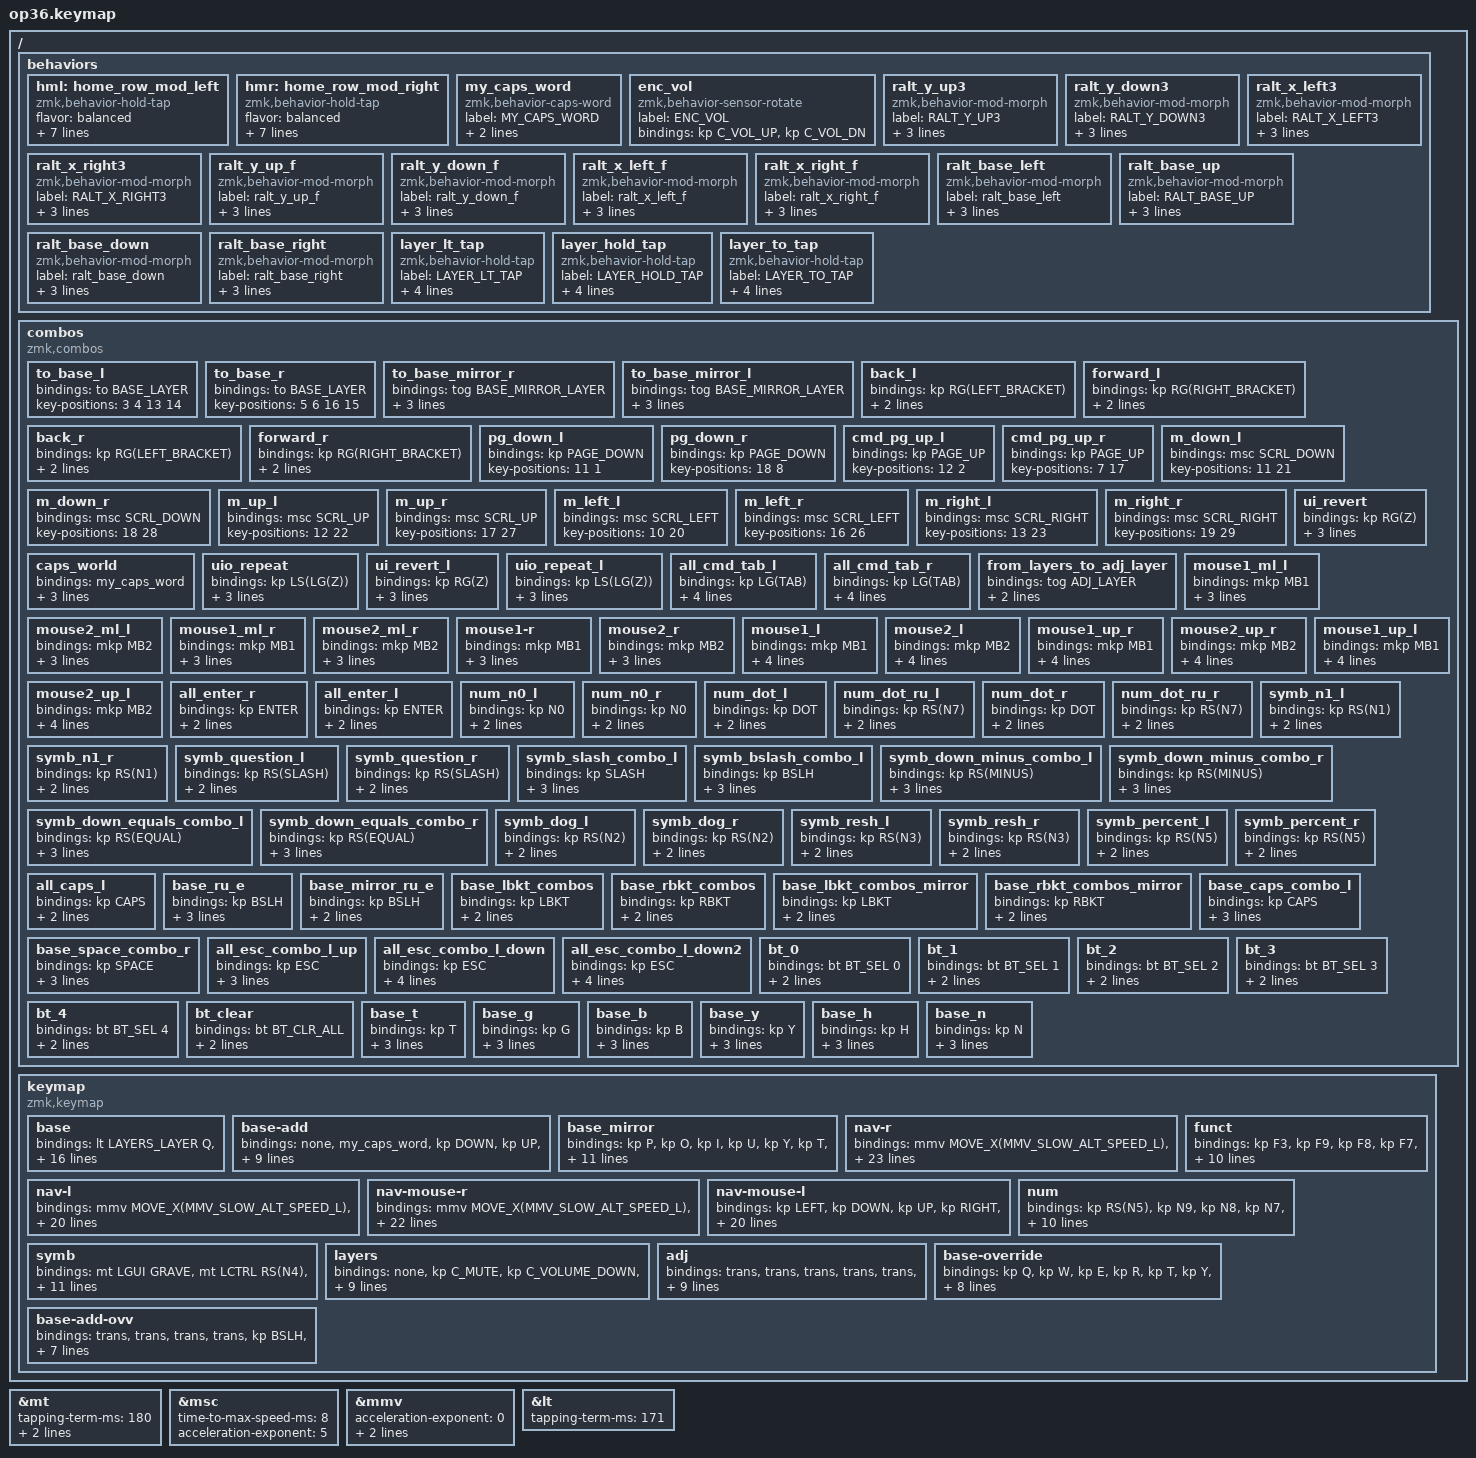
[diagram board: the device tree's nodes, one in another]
#define ZMK_POINTING_DEFAULT_SCRL_VAL 25

// Константы для перемещений

#define BASE_LAYER 0
#define BASE_ADD_LAYER 1
#define BASE_MIRROR_LAYER 2
#define NAV_R_LAYER 3
#define NAV_L_LAYER 4
#define NAV_MOUSE_R_LAYER 5
#define NAV_MOUSE_L_LAYER 6
#define FUNCT_LAYER 7
#define NUM_LAYER 8
#define SYMB_LAYER 9
#define LAYERS_LAYER 10
#define ADJ_LAYER 11
#define BASE_OVERRIDE_LAYER 12
#define BASE_ADD_OVERRIDE_LAYER 13

#define MMV_SLOW_ALT_SPEED 250
#define MMV_SLOW_ALT_SPEED_L -250
#define MMV_SLOW_ALT_SPEED_U -250
#define MMV_SLOW_ALT_SPEED_D 250
#define MMV_SLOW_ALT_SPEED_R 250

//

#define MMV_FAST_ALT_SPEED_X 950
#define MMV_FAST_ALT_SPEED_Y 950
#define MMV_FAST_ALT_SPEED_L -950
#define MMV_FAST_ALT_SPEED_U -950
#define MMV_FAST_ALT_SPEED_D 950
#define MMV_FAST_ALT_SPEED_R 950

//

#define MMV_FAST_SPEED_X 700
#define MMV_FAST_SPEED_Y 480
#define MMV_FAST_SPEED_L -MMV_FAST_SPEED_X
#define MMV_FAST_SPEED_U -MMV_FAST_SPEED_Y
#define MMV_FAST_SPEED_D MMV_FAST_SPEED_Y
#define MMV_FAST_SPEED_R MMV_FAST_SPEED_X

//
// 1100x750, 700x480, 600x410
#define MMV_SUPER_FAST_SPEED_X 1100
#define MMV_SUPER_FAST_SPEED_Y 750
#define MMV_SUPER_FAST_SPEED_L -MMV_SUPER_FAST_SPEED_X
#define MMV_SUPER_FAST_SPEED_U -MMV_SUPER_FAST_SPEED_Y
#define MMV_SUPER_FAST_SPEED_D MMV_SUPER_FAST_SPEED_Y
#define MMV_SUPER_FAST_SPEED_R MMV_SUPER_FAST_SPEED_X

#include <behaviors.dtsi>
#include <dt-bindings/zmk/bt.h>
#include <dt-bindings/zmk/keys.h>
#include <dt-bindings/zmk/outputs.h>
#include <dt-bindings/zmk/pointing.h>
#include "keys_ru.h"

&mt {
  tapping-term-ms = <180>;
  flavor = "balanced";
  quick-tap-ms = <50>;
};

&msc {
  time-to-max-speed-ms = <8>;
  acceleration-exponent = <5>;
};

&mmv {
  acceleration-exponent = <0>;
  time-to-max-speed-ms = <100>;
  delay-ms = <0>;
};

&lt {
  tapping-term-ms = <171>;
};

/ {
    behaviors {
        hml: home_row_mod_left {
            compatible = "zmk,behavior-hold-tap";
            #binding-cells = <2>;
            flavor = "balanced";
            require-prior-idle-ms = <150>;
            tapping-term-ms = <220>;
            quick-tap-ms = <175>;
            bindings = <&kp>, <&kp>;

            hold-trigger-key-positions = <5 6 7 8 9 15 16 17 18 19 25 26 27 28 29 33 34 35>;
            hold-trigger-on-release;
        };

        hmr: home_row_mod_right {
            compatible = "zmk,behavior-hold-tap";
            #binding-cells = <2>;
            flavor = "balanced";
            require-prior-idle-ms = <150>;
            tapping-term-ms = <220>;
            quick-tap-ms = <175>;
            bindings = <&kp>, <&kp>;

            hold-trigger-key-positions = <0 1 2 3 4 10 11 12 13 14 20 21 22 23 24 30 31 32>;
            hold-trigger-on-release;
        };        
        
         my_caps_word: my_caps_word {
                compatible = "zmk,behavior-caps-word";
                label = "MY_CAPS_WORD";
                #binding-cells = <0>;
                continue-list = <UNDERSCORE MINUS COMMA PERIOD SEMICOLON SPACE>;
             };
                    
            enc_vol: enc_vol {
              compatible = "zmk,behavior-sensor-rotate";
              label = "ENC_VOL";
              #sensor-binding-cells = <0>;
              bindings = <&kp C_VOL_UP>, <&kp C_VOL_DN>;
            };
            
            ralt_y_up3: ralt_y_up3 {
              compatible = "zmk,behavior-mod-morph";
              label = "RALT_Y_UP3";
              #binding-cells = <0>;
              bindings = 
                <&mmv MOVE_Y(MMV_SLOW_ALT_SPEED_U)>,
                <&mmv MOVE_Y(MMV_SUPER_FAST_SPEED_U)>;
              mods = <(MOD_RALT)>;
            };
        
            ralt_y_down3: ralt_y_down3 {
              compatible = "zmk,behavior-mod-morph";
              label = "RALT_Y_DOWN3";
              #binding-cells = <0>;
              bindings = 
                <&mmv MOVE_Y(MMV_SLOW_ALT_SPEED_D)>,
                <&mmv MOVE_Y(MMV_SUPER_FAST_SPEED_D)>;
              mods = <(MOD_RALT)>;
            };
        
            ralt_x_left3: ralt_x_left3 {
              compatible = "zmk,behavior-mod-morph";
              label = "RALT_X_LEFT3";
              #binding-cells = <0>;
              bindings =
                <&mmv MOVE_X(MMV_SLOW_ALT_SPEED_L)>,
                <&mmv MOVE_X(MMV_SUPER_FAST_SPEED_L)>;
              mods = <(MOD_RALT)>;
            };
        
            ralt_x_right3: ralt_x_right3 {
              compatible = "zmk,behavior-mod-morph";
              label = "RALT_X_RIGHT3";
              #binding-cells = <0>;
              bindings =
                <&mmv MOVE_X(MMV_SLOW_ALT_SPEED_R)>,
                <&mmv MOVE_X(MMV_SUPER_FAST_SPEED_R)>;
              mods = <(MOD_RALT)>;
            };
            
            /* */
            ralt_y_up_f: ralt_y_up_f {
                  compatible = "zmk,behavior-mod-morph";
                  label = "ralt_y_up_f";
                  #binding-cells = <0>;
                  bindings = 
                    <&kp UP_ARROW>,
                    <&mmv MOVE_Y(MMV_SUPER_FAST_SPEED_U)>;
                  mods = <(MOD_RALT)>;
                };
            
                ralt_y_down_f: ralt_y_down_f {
                  compatible = "zmk,behavior-mod-morph";
                  label = "ralt_y_down_f";
                  #binding-cells = <0>;
                  bindings = 
                    <&kp DOWN>,
                    <&mmv MOVE_Y(MMV_SUPER_FAST_SPEED_D)>;
                  mods = <(MOD_RALT)>;
                };
            
                ralt_x_left_f: ralt_x_left_f {
                  compatible = "zmk,behavior-mod-morph";
                  label = "ralt_x_left_f";
                  #binding-cells = <0>;
                  bindings =
                    <&kp LEFT>,
                    <&mmv MOVE_X(MMV_SUPER_FAST_SPEED_L)>;
                  mods = <(MOD_RALT)>;
                };
            
                ralt_x_right_f: ralt_x_right_f {
                  compatible = "zmk,behavior-mod-morph";
                  label = "ralt_x_right_f";
                  #binding-cells = <0>;
                  bindings =
                    <&kp RIGHT>,
                    <&mmv MOVE_X(MMV_SUPER_FAST_SPEED_R)>;
                  mods = <(MOD_RALT)>;
                };
            /* */
        
            /* mouse 0 layer */
            ralt_base_left: ralt_base_left {
              compatible = "zmk,behavior-mod-morph";
              label = "ralt_base_left";
              #binding-cells = <0>;
              bindings =
                <&kp M>,
                <&mmv MOVE_X(MMV_SUPER_FAST_SPEED_L)>;
              mods = <(MOD_RALT)>;
            };
        
            ralt_base_up: ralt_base_up {
              compatible = "zmk,behavior-mod-morph";
              label = "RALT_BASE_UP";
              #binding-cells = <0>;
              bindings = 
                <&kp COMMA>,
                <&mmv MOVE_Y(MMV_SUPER_FAST_SPEED_U)>;
              mods = <(MOD_RALT)>;
            };
        
            ralt_base_down: ralt_base_down {
              compatible = "zmk,behavior-mod-morph";
              label = "ralt_base_down";
              #binding-cells = <0>;
              bindings = 
                <&kp DOT>,
                <&mmv MOVE_Y(MMV_SUPER_FAST_SPEED_D)>;
              mods = <(MOD_RALT)>;
            };
        
            ralt_base_right: ralt_base_right {
              compatible = "zmk,behavior-mod-morph";
              label = "ralt_base_right";
              #binding-cells = <0>;
              bindings =
                <&kp SLASH>,
                <&mmv MOVE_X(MMV_SUPER_FAST_SPEED_R)>;
              mods = <(MOD_RALT)>;
            };
            /* end mouse 0 layer */
        
            layer_lt_tap: layer_lt_tap {
              compatible = "zmk,behavior-hold-tap";
              label = "LAYER_LT_TAP";
              #binding-cells = <2>;
              tapping-term-ms = <180>;
              quick-tap-ms = <0>;
              flavor = "tap-preferred";
              bindings = <&lt>, <&kp>;
            };
        
            layer_hold_tap: layer_hold_tap {
              compatible = "zmk,behavior-hold-tap";
              label = "LAYER_HOLD_TAP";
              #binding-cells = <2>;
              tapping-term-ms = <180>;
              quick-tap-ms = <0>;
              flavor = "tap-preferred";
              bindings = <&tog>, <&kp>;
            };
            
            layer_to_tap: layer_to_tap {
              compatible = "zmk,behavior-hold-tap";
              label = "LAYER_TO_TAP";
              #binding-cells = <2>;
              tapping-term-ms = <180>;
              quick-tap-ms = <0>;
              flavor = "tap-preferred";
              bindings = <&to>, <&kp>;
            };
    };

    combos {
        compatible = "zmk,combos";
                
        /* mo-start */
        to_base_l {
            bindings = <&to BASE_LAYER>;
            key-positions = <3 4 13 14>;
        };
        
        to_base_r {
            bindings = <&to BASE_LAYER>;
            key-positions = <5 6 16 15>;                    
        };
        
        to_base_mirror_r {
            bindings = <&tog BASE_MIRROR_LAYER>;
            key-positions = <0 1 2>;
            layers = <
                BASE_LAYER
                BASE_ADD_LAYER
                BASE_OVERRIDE_LAYER
                BASE_ADD_OVERRIDE_LAYER
                BASE_MIRROR_LAYER
            >;            
        };
        
        to_base_mirror_l {
            bindings = <&tog BASE_MIRROR_LAYER>;
            key-positions = <7 8 9>;
            layers = <
                BASE_LAYER
                BASE_ADD_LAYER
                BASE_OVERRIDE_LAYER
                BASE_ADD_OVERRIDE_LAYER
                BASE_MIRROR_LAYER
            >;                    
        };              
        /* mo-end */
        
        /* nav-start */
        back_l {
            bindings = <&kp RG(LEFT_BRACKET)>;
            key-positions = <12 13>;
            layers = <FUNCT_LAYER>;
        };

        forward_l {
            bindings = <&kp RG(RIGHT_BRACKET)>;
            key-positions = <11 12>;
            layers = <FUNCT_LAYER>;
        };

        back_r {
            bindings = <&kp RG(LEFT_BRACKET)>;
            key-positions = <16 17>;
            layers = <FUNCT_LAYER>;
        };

        forward_r {
            bindings = <&kp RG(RIGHT_BRACKET)>;
            key-positions = <17 18>;
            layers = <FUNCT_LAYER>;
        };

        /* nav-end */
        
        /* mouse-start */
        pg_down_l {
            bindings = <&kp PAGE_DOWN>;
            key-positions = <11 1>;
        };

        pg_down_r {
            bindings = <&kp PAGE_DOWN>;
            key-positions = <18 8>;
        };        
        
        cmd_pg_up_l {
            bindings = <&kp PAGE_UP>;
            key-positions = <12 2>;
        };

        cmd_pg_up_r {
            bindings = <&kp PAGE_UP>;
            key-positions = <7 17>;
        };

        m_down_l {
            bindings = <&msc SCRL_DOWN>;
            key-positions = <11 21>;
        };

        m_down_r {
            bindings = <&msc SCRL_DOWN>;
            key-positions = <18 28>;
        };

        m_up_l {
            bindings = <&msc SCRL_UP>;
            key-positions = <12 22>;
        };

        m_up_r {
            bindings = <&msc SCRL_UP>;
            key-positions = <17 27>;
        };

        m_left_l {
            bindings = <&msc SCRL_LEFT>;
            key-positions = <10 20>;
        };

        m_left_r {
            bindings = <&msc SCRL_LEFT>;
            key-positions = <16 26>;
        };

        m_right_l {
            bindings = <&msc SCRL_RIGHT>;
            key-positions = <13 23>;
        };

        m_right_r {
            bindings = <&msc SCRL_RIGHT>;
            key-positions = <19 29>;
        };        
        /* mouse-end */
        
        /* system-start */
        caps_world {
            bindings = <&my_caps_word>;
            key-positions = <16 13 17 12>;
            layers = <BASE_LAYER BASE_ADD_LAYER BASE_MIRROR_LAYER BASE_OVERRIDE_LAYER BASE_ADD_OVERRIDE_LAYER>;
        };        
        
        ui_revert {
            bindings = <&kp RG(Z)>;
            key-positions = <6 7>;
            layers = <FUNCT_LAYER BASE_OVERRIDE_LAYER LAYERS_LAYER>;
        };

        uio_repeat {
            bindings = <&kp LS(LG(Z))>;
            key-positions = <7 8>;
            layers = <FUNCT_LAYER BASE_OVERRIDE_LAYER LAYERS_LAYER>;
        };

        ui_revert_l {
            bindings = <&kp RG(Z)>;
            key-positions = <2 3>;
            layers = <FUNCT_LAYER BASE_OVERRIDE_LAYER LAYERS_LAYER>;
        };

        uio_repeat_l {
            bindings = <&kp LS(LG(Z))>;
            key-positions = <2 1>;
            layers = <FUNCT_LAYER BASE_OVERRIDE_LAYER LAYERS_LAYER>;
        };        
        
        all_cmd_tab_l {
            bindings = <&kp LG(TAB)>;
            key-positions = <2 1>;
            require-prior-idle-ms = <150>;
                        layers = <
                            BASE_LAYER
                            BASE_ADD_LAYER
                            BASE_MIRROR_LAYER
                            NAV_R_LAYER
                            NAV_L_LAYER
                            NAV_MOUSE_R_LAYER
                            NAV_MOUSE_L_LAYER
                            FUNCT_LAYER
                            NUM_LAYER
                            /* SYMB_LAYER */
                            LAYERS_LAYER
                            ADJ_LAYER
                            BASE_OVERRIDE_LAYER
                            BASE_ADD_OVERRIDE_LAYER
                        >;
        };

        all_cmd_tab_r {
            bindings = <&kp LG(TAB)>;
            require-prior-idle-ms = <150>;
            key-positions = <9 8>;
                        layers = <
                            BASE_LAYER
                            BASE_ADD_LAYER
                            BASE_MIRROR_LAYER
                            NAV_R_LAYER
                            NAV_L_LAYER
                            NAV_MOUSE_R_LAYER
                            NAV_MOUSE_L_LAYER
                            FUNCT_LAYER
                            NUM_LAYER
                            /* SYMB_LAYER */
                            LAYERS_LAYER
                            ADJ_LAYER
                            BASE_OVERRIDE_LAYER
                            BASE_ADD_OVERRIDE_LAYER
                        >;
        };        
        /* system-end */                

        from_layers_to_adj_layer {
            bindings = <&tog ADJ_LAYER>;
            key-positions = <9 8>;
            layers = <FUNCT_LAYER
            LAYERS_LAYER
            ADJ_LAYER>;
        };

        mouse1_ml_l {
            bindings = <&mkp MB1>;
            key-positions = <13 12>;
            require-prior-idle-ms = <150>;
            layers = <
            NAV_MOUSE_R_LAYER
            NAV_MOUSE_L_LAYER
            >;
        };

        mouse2_ml_l {
            bindings = <&mkp MB2>;
            key-positions = <13 12 11>;
            require-prior-idle-ms = <150>;
            layers = <
            NAV_MOUSE_R_LAYER
            NAV_MOUSE_L_LAYER
            >;
        };

        mouse1_ml_r {
            bindings = <&mkp MB1>;
            key-positions = <16 17>;
            require-prior-idle-ms = <150>;
            layers = <
            NAV_MOUSE_R_LAYER
            NAV_MOUSE_L_LAYER
            >;
        };

        mouse2_ml_r {
            bindings = <&mkp MB2>;
            key-positions = <16 17 18>;
            require-prior-idle-ms = <150>;
            layers = <
            NAV_MOUSE_R_LAYER
            NAV_MOUSE_L_LAYER
            >;
        };

        mouse1-r {
            bindings = <&mkp MB1>;
            key-positions = <26 27>;
            layers = <
                NAV_R_LAYER
                NAV_L_LAYER
                NAV_MOUSE_R_LAYER
                NAV_MOUSE_L_LAYER
                FUNCT_LAYER
                /* NUM_LAYER
                SYMB_LAYER */
                LAYERS_LAYER
                ADJ_LAYER
            >;            
        };

        mouse2_r {
            bindings = <&mkp MB2>;
            key-positions = <26 27 28>;
            layers = <
                NAV_R_LAYER
                NAV_L_LAYER
                NAV_MOUSE_R_LAYER
                NAV_MOUSE_L_LAYER
                FUNCT_LAYER
                /* NUM_LAYER
                SYMB_LAYER */
                LAYERS_LAYER
                ADJ_LAYER
            >;            
        };

        mouse1_l {
            bindings = <&mkp MB1>;
            key-positions = <22 23>;
            require-prior-idle-ms = <150>;
            layers = <
                BASE_LAYER
                BASE_ADD_LAYER
                BASE_MIRROR_LAYER
                NAV_R_LAYER
                NAV_L_LAYER
                NAV_MOUSE_R_LAYER
                NAV_MOUSE_L_LAYER
                FUNCT_LAYER
                /* NUM_LAYER
                SYMB_LAYER */
                LAYERS_LAYER
                ADJ_LAYER
                BASE_OVERRIDE_LAYER
                BASE_ADD_OVERRIDE_LAYER
            >;
        };

        mouse2_l {
            bindings = <&mkp MB2>;
            key-positions = <21 22 23>;
            require-prior-idle-ms = <150>;
            layers = <
                BASE_LAYER
                BASE_ADD_LAYER
                BASE_MIRROR_LAYER
                NAV_R_LAYER
                NAV_L_LAYER
                NAV_MOUSE_R_LAYER
                NAV_MOUSE_L_LAYER
                FUNCT_LAYER
                /* NUM_LAYER
                SYMB_LAYER */
                LAYERS_LAYER
                ADJ_LAYER
                BASE_OVERRIDE_LAYER
                BASE_ADD_OVERRIDE_LAYER
            >;            
        };

        mouse1_up_r {
            bindings = <&mkp MB1>;
            key-positions = <7 6>;
            require-prior-idle-ms = <150>;
            layers = <
            NAV_R_LAYER
            NAV_L_LAYER
            NAV_MOUSE_R_LAYER
            NAV_MOUSE_L_LAYER
            >;
        };

        mouse2_up_r {
            bindings = <&mkp MB2>;
            key-positions = <6 7 8>;
            require-prior-idle-ms = <150>;
            layers = <
            NAV_R_LAYER
            NAV_L_LAYER
            NAV_MOUSE_R_LAYER
            NAV_MOUSE_L_LAYER
            >;
        };

        mouse1_up_l {
            bindings = <&mkp MB1>;
            key-positions = <3 2>;
            require-prior-idle-ms = <150>;
            layers = <
            NAV_R_LAYER
            NAV_L_LAYER
            NAV_MOUSE_R_LAYER
            NAV_MOUSE_L_LAYER
            >;
        };

        mouse2_up_l {
            bindings = <&mkp MB2>;
            key-positions = <3 2 1>;
            require-prior-idle-ms = <150>;
            layers = <
            NAV_R_LAYER
            NAV_L_LAYER
            NAV_MOUSE_R_LAYER
            NAV_MOUSE_L_LAYER
            >;
        };
        
        /* kp-start */
        all_enter_r {
            bindings = <&kp ENTER>;
            key-positions = <27 28>;
            require-prior-idle-ms = <70>;
        };

        all_enter_l {
            bindings = <&kp ENTER>;
            key-positions = <22 21>;
            require-prior-idle-ms = <70>;
        };

        num_n0_l {
            bindings = <&kp N0>;
            key-positions = <23 22>;
            layers = <NUM_LAYER>;
        };

        num_n0_r {
            bindings = <&kp N0>;
            key-positions = <26 27>;
            layers = <NUM_LAYER>;
        };
        
        num_dot_l {
                    bindings = <&kp DOT>;
                    key-positions = <2 3>;
                    layers = <NUM_LAYER>;
                };
               
        num_dot_ru_l {
                    bindings = <&kp RS(N7)>;
                    key-positions = <1 2>;
                    layers = <NUM_LAYER>;
                };        
        
        num_dot_r {
                    bindings = <&kp DOT>;
                    key-positions = <6 7>;
                    layers = <NUM_LAYER>;
                };

        num_dot_ru_r {
                    bindings = <&kp RS(N7)>;
                    key-positions = <7 8>;
                    layers = <NUM_LAYER>;
                };                
        
        symb_n1_l {
            bindings = <&kp RS(N1)>;
            key-positions = <2 3>;
            layers = <SYMB_LAYER>;
        };
        
        symb_n1_r {
            bindings = <&kp RS(N1)>;
            key-positions = <6 7>;
            layers = <SYMB_LAYER>;      
        };
        
        symb_question_l {
            bindings = <&kp RS(SLASH)>;
            key-positions = <1 2>;
            layers = <SYMB_LAYER>;
        };
        
        symb_question_r {
            bindings = <&kp RS(SLASH)>;
            key-positions = <7 8>;
            layers = <SYMB_LAYER>;      
        };
        
        symb_slash_combo_l {
            bindings = <&kp SLASH>;
            key-positions = <12 13>;
            require-prior-idle-ms = <150>;
            layers = <SYMB_LAYER>;
        };
        
        symb_bslash_combo_l {
            bindings = <&kp BSLH>;
            key-positions = <11 12>;
            require-prior-idle-ms = <150>;
            layers = <SYMB_LAYER>;
        };        
        
        symb_down_minus_combo_l {
                    bindings = <&kp RS(MINUS)>;
                    key-positions = <11 12>;
                    require-prior-idle-ms = <150>;
                    layers = <SYMB_LAYER>;
                };
        
        symb_down_minus_combo_r {
            bindings = <&kp RS(MINUS)>;
            key-positions = <16 17>;
            require-prior-idle-ms = <150>;
            layers = <SYMB_LAYER>;
        };
        
        symb_down_equals_combo_l {
                    bindings = <&kp RS(EQUAL)>;
                    key-positions = <12 13>;
                    require-prior-idle-ms = <150>;
                    layers = <SYMB_LAYER>;
                };
        
        symb_down_equals_combo_r {
            bindings = <&kp RS(EQUAL)>;
            key-positions = <17 18>;
            require-prior-idle-ms = <150>;
            layers = <SYMB_LAYER>;
        };
        
        symb_dog_l {
            bindings = <&kp RS(N2)>;
            key-positions = <1 2 3>;
            layers = <SYMB_LAYER>;
        };
                        
        symb_dog_r {
            bindings = <&kp RS(N2)>;
            key-positions = <6 7 8>;
            layers = <SYMB_LAYER>;
        };                        

        symb_resh_l {
            bindings = <&kp RS(N3)>;
            key-positions = <11 12 13>;
            layers = <SYMB_LAYER>;
        };
        
        symb_resh_r {
            bindings = <&kp RS(N3)>;
            key-positions = <16 17 18>;
            layers = <SYMB_LAYER>;
        };
        
        symb_percent_l {
            bindings = <&kp RS(N5)>;
            key-positions = <21 22 23>;
            layers = <SYMB_LAYER>;      
        };        
                
        symb_percent_r {
            bindings = <&kp RS(N5)>;
            key-positions = <26 27 28>;
            layers = <SYMB_LAYER>;      
        };                                               
        
        all_caps_l {
            bindings = <&kp CAPS>;
            key-positions = <40 41 24 23>;
            require-prior-idle-ms = <150>;
        };        
        
        base_ru_e {
            bindings = <&kp BSLH>;
            key-positions = <2 3>;
            layers = <BASE_LAYER BASE_ADD_LAYER BASE_OVERRIDE_LAYER BASE_ADD_OVERRIDE_LAYER>;
        };
        
        base_mirror_ru_e {
            bindings = <&kp BSLH>;
            key-positions = <6 7>;
            layers = <BASE_MIRROR_LAYER>;
        };        
        
        base_lbkt_combos {
            bindings = <&kp LBKT>;
            key-positions = <6 7>;
            layers = <BASE_LAYER BASE_ADD_LAYER>;
        };

        base_rbkt_combos {
            bindings = <&kp RBKT>;
            key-positions = <8 7>;
            layers = <BASE_LAYER BASE_ADD_LAYER>;
        };
        
        base_lbkt_combos_mirror {
            bindings = <&kp LBKT>;
            key-positions = <2 3>;
            layers = <BASE_MIRROR_LAYER>;
        };

        base_rbkt_combos_mirror {
            bindings = <&kp RBKT>;
            key-positions = <1 2>;
            layers = <BASE_MIRROR_LAYER>;
        };        

        base_caps_combo_l {
            bindings = <&kp CAPS>;
            key-positions = <14 13>;
            layers = <BASE_LAYER BASE_ADD_LAYER BASE_OVERRIDE_LAYER BASE_ADD_OVERRIDE_LAYER>;
        };
        
        base_space_combo_r {
            bindings = <&kp SPACE>;
            key-positions = <28 29>;
            layers = <BASE_LAYER BASE_ADD_LAYER BASE_OVERRIDE_LAYER BASE_ADD_OVERRIDE_LAYER>;
        };        

        all_esc_combo_l_up {
            bindings = <&kp ESC>;
            key-positions = <0 1>;
                        layers = <
                            BASE_LAYER
                            BASE_ADD_LAYER
                            BASE_MIRROR_LAYER
                            NAV_R_LAYER
                            NAV_L_LAYER
                            NAV_MOUSE_R_LAYER
                            NAV_MOUSE_L_LAYER
                            FUNCT_LAYER
                            NUM_LAYER
                            /* SYMB_LAYER */
                            LAYERS_LAYER
                            ADJ_LAYER
                            BASE_OVERRIDE_LAYER
                            BASE_ADD_OVERRIDE_LAYER
                        >;
        };
        
        all_esc_combo_l_down {
            bindings = <&kp ESC>;
            key-positions = <23 24>;
                        layers = <
                            BASE_LAYER
                            BASE_ADD_LAYER
                            BASE_MIRROR_LAYER
                            NAV_R_LAYER
                            NAV_L_LAYER
                            NAV_MOUSE_R_LAYER
                            NAV_MOUSE_L_LAYER
                            FUNCT_LAYER
                            NUM_LAYER
                            /* SYMB_LAYER */
                            LAYERS_LAYER
                            ADJ_LAYER
                            BASE_OVERRIDE_LAYER
                            BASE_ADD_OVERRIDE_LAYER
                        >;
            require-prior-idle-ms = <150>;
        };
        
        all_esc_combo_l_down2 {
                    bindings = <&kp ESC>;
                    key-positions = <20 21>;
                                layers = <
                                    BASE_LAYER
                                    BASE_ADD_LAYER
                                    BASE_MIRROR_LAYER
                                    NAV_R_LAYER
                                    NAV_L_LAYER
                                    NAV_MOUSE_R_LAYER
                                    NAV_MOUSE_L_LAYER
                                    FUNCT_LAYER
                                    NUM_LAYER
                                    /* SYMB_LAYER */
                                    LAYERS_LAYER
                                    ADJ_LAYER
                                    BASE_OVERRIDE_LAYER
                                    BASE_ADD_OVERRIDE_LAYER
                                >;
            require-prior-idle-ms = <150>;
                };                                        
        /* kp-end */
        
        /* bt */
        bt_0 {
            bindings = <&bt BT_SEL 0>;
            key-positions = <0 1 2>;
            layers = <LAYERS_LAYER>;
        };

        bt_1 {
            bindings = <&bt BT_SEL 1>;
            key-positions = <1 2 3>;
            layers = <LAYERS_LAYER>;
        };

        bt_2 {
            bindings = <&bt BT_SEL 2>;
            key-positions = <2 3 4>;
            layers = <LAYERS_LAYER>;
        };

        bt_3 {
            bindings = <&bt BT_SEL 3>;
            key-positions = <5 6 7>;
            layers = <LAYERS_LAYER>;
        };

        bt_4 {
            bindings = <&bt BT_SEL 4>;
            key-positions = <6 7 8>;
            layers = <LAYERS_LAYER>;
        };

        bt_clear {
            bindings = <&bt BT_CLR_ALL>;
            key-positions = <2 3 4 5 6 7>;
            layers = <LAYERS_LAYER>;
        };        
        /* bt-end */
        
        /* 4*3-start */
        base_t {
            bindings = <&kp T>;
            key-positions = <1 3>;
            layers = <BASE_LAYER BASE_ADD_LAYER NAV_R_LAYER NAV_L_LAYER NUM_LAYER FUNCT_LAYER>;
        };

        base_g {
            bindings = <&kp G>;
            key-positions = <11 13>;
            layers = <BASE_LAYER BASE_ADD_LAYER NAV_R_LAYER NAV_L_LAYER NUM_LAYER FUNCT_LAYER>;
        };
        
        base_b {
            bindings = <&kp B>;
            key-positions = <21 23>;
            layers = <BASE_LAYER BASE_ADD_LAYER NAV_R_LAYER NAV_L_LAYER NUM_LAYER FUNCT_LAYER>;
        };
        
        base_y {
            bindings = <&kp Y>;
            key-positions = <6 8>;
            layers = <BASE_LAYER BASE_ADD_LAYER NAV_R_LAYER NAV_L_LAYER NUM_LAYER FUNCT_LAYER>;
        };
        
        base_h {
            bindings = <&kp H>;
            key-positions = <16 18>;
            layers = <BASE_LAYER BASE_ADD_LAYER NAV_R_LAYER NAV_L_LAYER NUM_LAYER FUNCT_LAYER>;
        };
        
        base_n {
            bindings = <&kp N>;
            key-positions = <26 28>;
            layers = <BASE_LAYER BASE_ADD_LAYER NAV_R_LAYER NAV_L_LAYER NUM_LAYER FUNCT_LAYER>;
        };
                                                 
        /* 4*3-end */        
    };

keymap {
    compatible = "zmk,keymap";

    base {
      bindings = <
        /* base B L */
        &lt LAYERS_LAYER Q
        &lt BASE_MIRROR_LAYER W
        &lt BASE_MIRROR_LAYER E
        &kp R
        &kp T
        /* base B R */
        &kp Y
        &kp U
        &lt BASE_MIRROR_LAYER I
        &lt BASE_MIRROR_LAYER O
        &lt LAYERS_LAYER P

        /* base C L */
        &hml LGUI A
        &hml LCTRL S
        &hml LALT D
        &hml LSHFT F
        &lt BASE_ADD_LAYER G
        /* base C R */
        &lt BASE_ADD_LAYER H
        &hmr RSHIFT J
        &hmr RALT K
        &hmr RCTRL L
        &hmr RGUI SEMI

        /* base D L */
        &lt NUM_LAYER Z
        &kp X
        &kp C
        &kp V
        &kp B                                
        /* base D R */
        &kp N
        &kp M
        &kp COMMA
        &kp DOT
        &lt SYMB_LAYER SQT

        /* base T L */
        &lt SYMB_LAYER TAB
        &lt NAV_L_LAYER SPACE
        &lt FUNCT_LAYER DEL
        /* base T R */
        &lt FUNCT_LAYER ESC
        &lt NAV_R_LAYER RG(RC(SPACE))
        &lt NUM_LAYER BACKSPACE
      >;
      display-name = "base";
    };
    
    base-add{
      bindings = <
        /* base-add B L */
        &none
        &my_caps_word
        &kp DOWN
        &kp UP        
        &none
        /* base-add B R */
        &none                   
        &kp UP
        &kp DOWN
        &my_caps_word        
        &none

        /* base-add C L */
        &none
        &kp LS(LA(L))
        &msc SCRL_DOWN
        &msc SCRL_UP
        &none
        /* base-add C R */
        &none
        &msc SCRL_UP
        &msc SCRL_DOWN
        &kp LS(LA(L))                
        &none
        
        /* base-add D L */
        &none
        &kp LS(LA(K))
        &kp PAGE_DOWN
        &kp PAGE_UP
        &none
        /* base-add D R */
        &none        
        &kp PAGE_UP
        &kp PAGE_DOWN
        &kp LS(LA(K))
        &none

        /* base-add T L */
        &trans
        &trans
        &trans
        /* base-add T R */
        &trans
        &trans
        &trans
      >;
      display-name = "base-add";
    };
    
    base_mirror {
      bindings = <      
      /* base-m B L */
      &kp P
      &kp O
      &kp I
      &kp U
      &kp Y
      /* base-m B R */
      &kp T
      &kp R
      &kp E
      &kp W
      &kp Q
              
              /* base-m C L */
              &hml LGUI SEMI
              &hml LCTRL L
              &hml LALT K
              &hml LSHFT J
              &kp H
              /* base-m C R */
              &kp G
              &hmr RSHIFT F
              &hmr RALT D
              &hmr RCTRL S
              &hmr RGUI A
      
              /* base-m D L */
              &lt NUM_LAYER SQT
              &kp DOT
              &kp COMMA
              &kp M
              &lt LAYERS_LAYER N
              /* base-m D R */
              &lt LAYERS_LAYER B
              &kp V
              &kp C
              &kp X
              &lt NUM_LAYER Z

              /* base-m T L */
              &lt SYMB_LAYER BACKSPACE
              &lt NAV_L_LAYER RG(RC(SPACE))
              &lt FUNCT_LAYER ESC
              /* base-m T R */
              &lt FUNCT_LAYER DEL
              &lt NAV_R_LAYER SPACE
              &lt SYMB_LAYER TAB
            >;
      display-name = "base-mirror";
    };
    
    nav-r {
      bindings = <
        /* nav-r B L */
        &mmv MOVE_X(MMV_SLOW_ALT_SPEED_L)
        &mmv MOVE_Y(MMV_SLOW_ALT_SPEED_D)
        &mmv MOVE_Y(MMV_SLOW_ALT_SPEED_U)                    
        &mmv MOVE_X(MMV_SLOW_ALT_SPEED_R)
        &to BASE_LAYER
        /* nav-r B R */
        &to BASE_LAYER
        &mmv MOVE_X(MMV_SLOW_ALT_SPEED_L)
        &mmv MOVE_Y(MMV_SLOW_ALT_SPEED_U)
        &mmv MOVE_Y(MMV_SLOW_ALT_SPEED_D)
        &mmv MOVE_X(MMV_SLOW_ALT_SPEED_R)
        
        /* nav-r C L */        
        &kp LGUI
        &kp LCTRL
        &kp LALT
        &kp LSHFT
        &msc SCRL_UP
        /* nav-r C R */
        &msc SCRL_UP
        &kp LEFT_ARROW
        &kp UP
        &kp DOWN
        &kp RIGHT_ARROW

        /* nav-r D L */
        &mmv MOVE_X(MMV_SUPER_FAST_SPEED_L)
        &mmv MOVE_Y(MMV_SUPER_FAST_SPEED_D)
        &mmv MOVE_Y(MMV_SUPER_FAST_SPEED_U)
        &mmv MOVE_X(MMV_SUPER_FAST_SPEED_R)
        &msc SCRL_DOWN
        /* nav-r D R */
        &msc SCRL_DOWN
        &mmv MOVE_X(MMV_FAST_SPEED_L)
        &mmv MOVE_Y(MMV_FAST_SPEED_U)
        &mmv MOVE_Y(MMV_FAST_SPEED_D)        
        &mmv MOVE_X(MMV_FAST_SPEED_R)

        /* nav-r T L */
        &trans
        &lt BASE_OVERRIDE_LAYER SPACE
        &trans
        /* nav-r T R */
        &trans
        &lt BASE_OVERRIDE_LAYER RG(RC(SPACE))  
        &trans
      >;
      display-name = "nav-r";
    };
    
nav-l {
  bindings = <
    /* nav-l B L */
    &mmv MOVE_X(MMV_SLOW_ALT_SPEED_L)
    &mmv MOVE_Y(MMV_SLOW_ALT_SPEED_D)
    &mmv MOVE_Y(MMV_SLOW_ALT_SPEED_U)                    
    &mmv MOVE_X(MMV_SLOW_ALT_SPEED_R)
    &to BASE_LAYER
    /* nav-l B R */
    &to BASE_LAYER
    &kp LEFT_ARROW      
    &kp UP                      
    &kp DOWN
    &kp RIGHT_ARROW
    /* nav-l C L */
    &kp LEFT_ARROW
    &kp DOWN
    &kp UP
    &kp RIGHT_ARROW   
    &msc SCRL_UP
    /* nav-l C R */
    &msc SCRL_UP
    &kp LSHFT
    &kp LALT
    &kp LCTRL
    &kp LGUI

    /* nav-l D L */
    &mmv MOVE_X(MMV_SUPER_FAST_SPEED_L)
    &mmv MOVE_Y(MMV_SUPER_FAST_SPEED_D)
    &mmv MOVE_Y(MMV_SUPER_FAST_SPEED_U)                    
    &mmv MOVE_X(MMV_SUPER_FAST_SPEED_R)
    &msc SCRL_DOWN    
    /* nav-l D R */
    &msc SCRL_DOWN
    &mmv MOVE_X(MMV_FAST_SPEED_L)
    &mmv MOVE_Y(MMV_FAST_SPEED_U)        
    &mmv MOVE_Y(MMV_FAST_SPEED_D)    
    &mmv MOVE_X(MMV_FAST_SPEED_R)
    /* nav-l T L */            
    &trans
    &lt BASE_OVERRIDE_LAYER SPACE
    &trans
    /* nav-l T R */
    &trans
    &lt BASE_OVERRIDE_LAYER RG(RC(SPACE))
    &trans
  >;
  display-name = "nav-l";
};

nav-mouse-r {
      bindings = <
              /* nav-m-r B L */
              &mmv MOVE_X(MMV_SLOW_ALT_SPEED_L)
              &mmv MOVE_Y(MMV_SLOW_ALT_SPEED_U)
              &mmv MOVE_Y(MMV_SLOW_ALT_SPEED_D)                                  
              &mmv MOVE_X(MMV_SLOW_ALT_SPEED_R)
              &to BASE_LAYER              
              /* nav-m-r B R */
              &to BASE_LAYER
              &kp LEFT_ARROW
              &kp UP
              &kp DOWN
              &kp RIGHT_ARROW
              /* nav-m-r C L */        
              &kp LGUI
              &kp LCTRL
              &kp LALT
              &kp LSHFT
              &msc SCRL_UP
              /* nav-m-r C R */
              &msc SCRL_UP
              &mmv MOVE_X(MMV_FAST_SPEED_L)
              &mmv MOVE_Y(MMV_FAST_SPEED_U)
              &mmv MOVE_Y(MMV_FAST_SPEED_D)        
              &mmv MOVE_X(MMV_FAST_SPEED_R)        
      
              /* nav-m-r D L */
              &mmv MOVE_X(MMV_SUPER_FAST_SPEED_L)
              &mmv MOVE_Y(MMV_SUPER_FAST_SPEED_D)
              &mmv MOVE_Y(MMV_SUPER_FAST_SPEED_U)
              &mmv MOVE_X(MMV_SUPER_FAST_SPEED_R)
              &msc SCRL_DOWN
              /* nav-m-r D R */
              &msc SCRL_DOWN
              &mmv MOVE_X(MMV_SLOW_ALT_SPEED_L)
              &mmv MOVE_Y(MMV_SLOW_ALT_SPEED_U)
              &mmv MOVE_Y(MMV_SLOW_ALT_SPEED_D)
              &mmv MOVE_X(MMV_SLOW_ALT_SPEED_R)
      
              /* nav-m-r T L */
              &trans
              &lt BASE_OVERRIDE_LAYER SPACE
              &trans
              /* nav-m-r T R */
              &trans
              &lt BASE_OVERRIDE_LAYER RG(RC(SPACE))
              &trans
            >;
      display-name = "nav-mouse-r";
    };

  nav-mouse-l {
    bindings = <
            /* nav-m-l B L */
            &kp LEFT
            &kp DOWN
            &kp UP
            &kp RIGHT
            &to BASE_LAYER
            /* nav-m-l B R */
            &to BASE_LAYER
            &kp LEFT_ARROW
            &kp UP
            &kp DOWN          
            &kp RIGHT_ARROW
                      
            /* nav-m-l C L */        
            &mmv MOVE_X(MMV_SUPER_FAST_SPEED_L)
            &mmv MOVE_Y(MMV_SUPER_FAST_SPEED_D)
            &mmv MOVE_Y(MMV_SUPER_FAST_SPEED_U)
            &mmv MOVE_X(MMV_SUPER_FAST_SPEED_R) 
            &msc SCRL_UP
            /* nav-m-l C R */
            &msc SCRL_UP
            &kp LSHFT
            &kp LALT
            &kp LCTRL       
            &kp LGUI        
    
            /* nav-m-l D L */
            &mmv MOVE_X(MMV_SLOW_ALT_SPEED_L)            
            &mmv MOVE_Y(MMV_SLOW_ALT_SPEED_D)
            &mmv MOVE_Y(MMV_SLOW_ALT_SPEED_U)
            &mmv MOVE_X(MMV_SLOW_ALT_SPEED_R)
            &msc SCRL_DOWN
            /* nav-m-l D R */
            &msc SCRL_DOWN
            &mmv MOVE_X(MMV_FAST_SPEED_L) 
            &mmv MOVE_Y(MMV_FAST_SPEED_U)
            &mmv MOVE_Y(MMV_FAST_SPEED_D)        
            &mmv MOVE_X(MMV_FAST_SPEED_R)
    
            /* nav-m-l T L */
            &trans
            &lt BASE_OVERRIDE_LAYER SPACE
            &trans
            /* nav-m-l T R */
            &trans
            &lt BASE_OVERRIDE_LAYER RG(RC(SPACE))
            &trans
          >;
    display-name = "nav-mouse-l";
  };

    funct {
      bindings = <
        /* funct B L */
        &kp F3
        &kp F9
        &kp F8
        &kp F7
        &to NAV_MOUSE_L_LAYER        
        /* funct B R */
        &to NAV_MOUSE_R_LAYER
        &kp F7
        &kp F8
        &kp F9
        &kp F3

        /* funct C L */
        &hml LGUI F2
        &hml LCTRL F6
        &hml LALT F5
        &hml LSHIFT F4
        &tog NAV_L_LAYER
        
        /* funct C R */
        &tog NAV_R_LAYER
        &hmr RSHFT F4
        &hmr RALT F5
        &hmr RCTRL F6
        &hmr RGUI F2

        /* funct D L */
        &kp F1
        &kp F12
        &kp F11
        &kp F10
        &to BASE_LAYER
        /* funct D R */
        &to BASE_LAYER
        &kp F10
        &kp F11
        &kp F12
        &kp F1

        /* num T L */
        &kp TAB
        &kp SPACE
        &kp DELETE
        /* num T R */
        &kp ESC
        &kp CAPSLOCK
        &kp BACKSPACE
      >;
      display-name = "funct";
    };

    num {
      bindings = <
        /* num B L */
        &kp RS(N5)
        &kp N9
        &kp N8
        &kp N7
        &kp EQUAL
        /* num B R */
        &kp EQUAL
        &kp N7
        &kp N8
        &kp N9
        &kp RS(N5)

        /* num C L */
        &hml LGUI N0
        &hml LCTRL N6
        &hml LALT N5
        &hml LSHFT N4
        &kp MINUS
        /* num C R */
        &kp MINUS
        &hmr RSHIFT N4
        &hmr RIGHT_ALT N5
        &hmr RCTRL N6
        &hmr RGUI N0

        /* num D L */
        &kp RS(MINUS)
        &kp N3
        &kp N2
        &kp N1
        &kp EQUAL
        /* num D R */
        &kp EQUAL
        &kp N1
        &kp N2
        &kp N3
        &kp RS(MINUS)

        /* num T L */
        &kp TAB
        &kp SPACE
        &kp DELETE
        /* num T R */
        &kp ESC
        &kp CAPSLOCK
        &kp BACKSPACE
      >;
      label = "num";
    };
    
    
    symb {
      bindings = <
        /* symb B L */        
        &mt LGUI GRAVE
        &mt LCTRL RS(N4)
        &kp LEFT_PARENTHESIS
        &kp RIGHT_PARENTHESIS
        &none
        /* symb B R */
        &none
        &kp LEFT_PARENTHESIS
        &kp RIGHT_PARENTHESIS        
        &mt RCTRL RS(N4)
        &mt RGUI GRAVE

        /* symb C L */
        &kp BSLH
        &kp SLASH
        &mt LALT EQUAL
        &mt LSHFT MINUS
        &none
        /* symb C R */
        &none
        &mt RSHFT MINUS
        &mt RALT EQUAL
        &kp SLASH
        &kp BSLH

        /* symb D L */        
        &kp RS(N5)
        &kp RS(N7)        
        &kp RS(N6)
        &kp RS(N8)
        &none
        /* symb D R */
        &none
        &kp RS(N8)
        &kp RS(N6)
        &kp RS(N7)
        &kp RS(N5)

        /* symb T L */
        &kp TAB
        &kp SPACE
        &kp DELETE
        /* symb T R */
        &kp ESC
        &kp CAPSLOCK
        &kp BACKSPACE
      >;
      label = "symb";
    };
    

    layers {
      bindings = <
        /* layers B L */
        &none
        &kp C_MUTE
        &kp C_VOLUME_DOWN
        &kp C_VOLUME_UP
        &to BASE_LAYER
        /* layers B R */        
        &to BASE_LAYER              
        &kp C_VOLUME_UP
        &kp C_VOLUME_DOWN
        &kp C_MUTE
        &none

        /* layers C L */
        &none
        &kp C_PLAY_PAUSE
        &kp C_PREV        
        &kp C_NEXT      
        &none
        /* layers C R */
        &none
        &kp C_NEXT
        &kp C_PREV
        &kp C_PLAY_PAUSE
        &none

        /* layers D L */
        &none
        &none
        &kp F14
        &kp F15      
        &none
        /* layers D R */
        &none
        &kp F15
        &kp F14
        &none
        &none
        
        /* layers T L */
        &none
        &none
        &none
        /* layers T R */
        &none
        &none
        &none
      >;
      label = "layers";
    };


    adj {
      bindings = <        
        /* adj B L */
        &trans
        &trans
        &trans
        &trans
        &trans
        /* adj B L */        
        &trans
        &trans
        &trans
        &trans
        &studio_unlock
        
        /* adj C L */
        &trans
        &trans
        &trans
        &trans
        &trans
                
        /* adj C R */
        &out OUT_BLE
        &kp C_VOL_DN
        &kp C_MUTE
        &kp C_VOL_UP
        &trans        
        /* adj C R */
        &to BASE_LAYER
        &trans
        &trans
        &trans
        &trans
        
        /* layers D L */
        &trans
        &out OUT_USB
        &kp C_PREV
        &kp C_PLAY_PAUSE
        &kp C_NEXT
        /* layers D R */
        &to BASE_LAYER
        &trans
        &trans
        &trans
        &trans
        
        /* adj T L */
        &trans
        &trans
        &trans
        /* adj T R */
        &trans
        &trans
        &trans
      >;
      display-name = "Adjust";
    };
    
    base-override {
      bindings = <
        /* base-o B L */
        &kp Q
        &kp W
        &kp E
        &kp R
        &kp T
        /* base-o B R */
        &kp Y
        &kp U
        &kp I
        &kp O
        &kp P

        /* base-o C L */
        &hml LGUI A
        &hml LCTRL S
        &hml LALT D
        &hml LSHFT F
        &kp G
        /* base-o C R */
        &kp H
        &hmr RSHIFT J
        &hmr RALT K
        &hmr RCTRL L
        &hmr RGUI SEMI

        /* base-o D L */
        &lt NUM_LAYER Z
        &kp X
        &kp C
        &kp V
        &kp B
        /* base-o D R */
        &kp N
        &kp M
        &kp COMMA
        &kp DOT
        &lt SYMB_LAYER SQT

        /* base-o T L */
        &kp TAB
        &kp SPACE
        &kp DEL
        /* base-o T R */
        &kp ESC
        &kp CAPS
        &kp BACKSPACE
      >;
      display-name = "base-override";
    };    


        base-add-ovv{
          bindings = <
            /* base-add-ovv B L */
            &trans
            &trans
            &trans
            &trans
            &kp BSLH
            /* base-add-ovv B R */
            &trans
            &trans
            &trans
            &kp GRAVE
            &trans        
    
            /* base-add-ovv C L */
            &trans
            &trans
            &trans
            &trans
            &trans
            /* base-add-ovv C R */
            &trans
            &trans
            &trans
            &kp SQT
            &trans
            
            /* base-add-ovv D L */
            &trans
            &kp MINUS
            &kp EQUAL
            &trans
            &trans
            /* base-add-ovv D R */
            &trans
            &kp LBKT
            &kp RBKT
            &kp BSLH
    
            /* base-add-ovv T L */
            &trans
            &trans
            &trans
            &trans
            /* base-add T R */
            &trans
            &trans
            &trans
            &trans
          >;
          display-name = "base-add-ovv";
        };
    };
};
